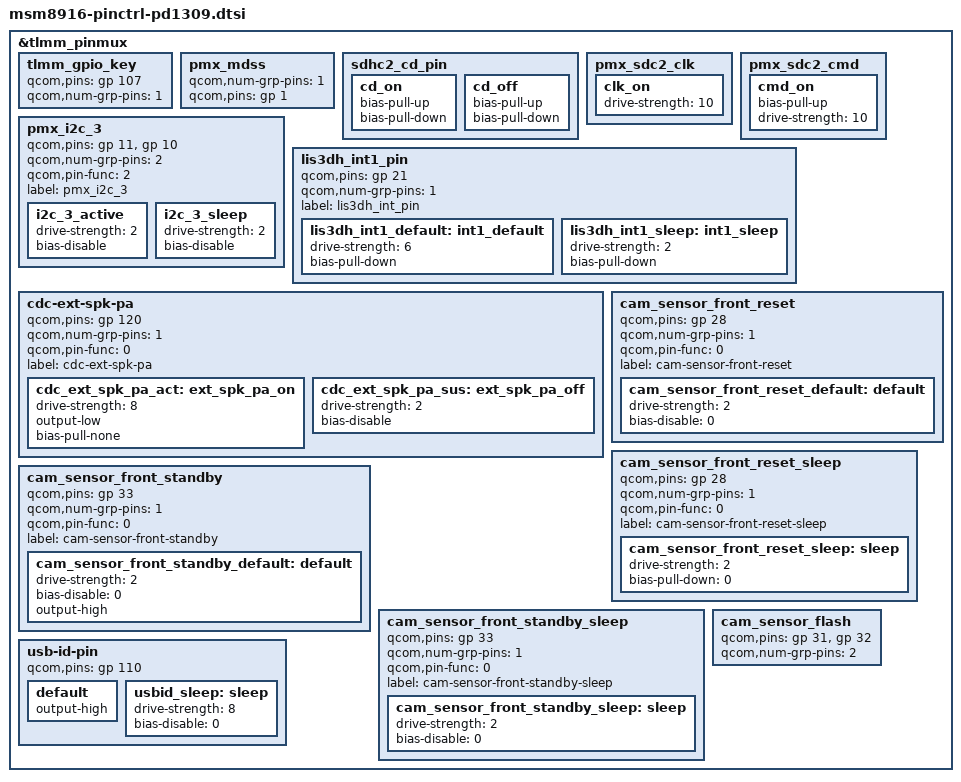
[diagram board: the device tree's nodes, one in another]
/* Copyright (c) 2020, The Linux Foundation. All rights reserved.
*  Copyright (c) 2020, the_shahnawaz_sheikh (sheikhshahnawaz41299).
*
* This program is free software; you can redistribute it and/or modify
* it under the terms of the GNU General Public License version 2 and
* only version 2 as published by the Free Software Foundation.
*
* This program is distributed in the hope that it will be useful,
* but WITHOUT ANY WARRANTY; without even the implied warranty of
* MERCHANTABILITY or FITNESS FOR A PARTICULAR PURPOSE.  See the
* GNU General Public License for more details.
*/
 
&tlmm_pinmux {

    tlmm_gpio_key {
		        /delete-property/ qcom,num-grp-pins;
				/delete-property/ qcom,pins;
				qcom,pins = <&gp 107>;
				qcom,num-grp-pins = <1>;
		};
    pmx_mdss {
				/delete-property/ qcom,num-grp-pins;
				/delete-property/ qcom,pins;
				qcom,num-grp-pins = <1>;
				qcom,pins = <&gp 1>;
		};
    
    /delete-node/ spi2_active;
		/delete-node/ spi2_suspend;
		/delete-node/ spi2_cs2_active;
		/delete-node/ spi2_cs2_suspend;
        
    sdhc2_cd_pin {

				cd_on {
					bias-pull-up;
					bias-pull-down;
				};

				cd_off {
                /delete-property/ bias-disable;
					bias-pull-up;
					bias-pull-down;
				};
		};
    
    pmx_sdc2_clk {
				clk_on {
					drive-strength = <10>;
				};
		};
	
	pmx_sdc2_cmd {
				cmd_on {
					bias-pull-up;
					drive-strength = <10>;
				};
			};
    
	pmx_i2c_3 {
		/* CLK, DATA */
		qcom,pins = <&gp 11>, <&gp 10>;
		qcom,num-grp-pins = <2>;
		qcom,pin-func = <2>;
		label = "pmx_i2c_3";

		i2c_3_active: i2c_3_active {
			drive-strength = <2>; /* 2 MA */
			bias-disable;		  /* No PULL */
		};

		i2c_3_sleep: i2c_3_sleep {
			drive-strength = <2>; /* 2 MA */
			bias-disable;		  /* No PULL */
		};
	};

	lis3dh_int1_pin {
		qcom,pins = <&gp 21>;
		qcom,num-grp-pins = <1>;
		label = "lis3dh_int_pin";
		lis3dh_int1_default: int1_default {
			drive-strength = <6>;
			bias-pull-down;
		};
		lis3dh_int1_sleep: int1_sleep {
			drive-strength = <2>;
			bias-pull-down;
		};
	};

	cdc-ext-spk-pa {
		qcom,pins = <&gp 120>;
		qcom,num-grp-pins = <1>;
		qcom,pin-func = <0>;
		label = "cdc-ext-spk-pa";
		cdc_ext_spk_pa_act: ext_spk_pa_on {
			drive-strength = <8>;
			output-low;
			bias-pull-none;
		};
		cdc_ext_spk_pa_sus: ext_spk_pa_off {
			drive-strength = <2>;
			bias-disable;
		};
	};

        
    cam_sensor_front_reset {
				qcom,pins = <&gp 28>;
				qcom,num-grp-pins = <1>;
				qcom,pin-func = <0>;
				label = "cam-sensor-front-reset";

				cam_sensor_front_reset_default:default {
					drive-strength = <2>;
					bias-disable = <0>;
					
				};
			};

			cam_sensor_front_reset_sleep {
				qcom,pins = <&gp 28>;
				qcom,num-grp-pins = <1>;
				qcom,pin-func = <0>;
				label = "cam-sensor-front-reset-sleep";

				cam_sensor_front_reset_sleep: sleep {
					drive-strength = <2>;
					bias-pull-down = <0>;
					
				};
			};

			cam_sensor_front_standby {
				qcom,pins = <&gp 33>;
				qcom,num-grp-pins = <1>;
				qcom,pin-func = <0>;
				label = "cam-sensor-front-standby";

			cam_sensor_front_standby_default: default {
					drive-strength = <2>;
					bias-disable = <0>;
					output-high;
					
				};
			};

			cam_sensor_front_standby_sleep {
				qcom,pins = <&gp 33>;
				qcom,num-grp-pins = <1>;
				qcom,pin-func = <0>;
				label = "cam-sensor-front-standby-sleep";

				cam_sensor_front_standby_sleep: sleep {
					drive-strength = <2>;
					bias-disable = <0>;
					
				};
			};
			
			cam_sensor_flash {
			    /delete-property/ qcom,num-grp-pins;
				/delete-property/ qcom,pins;
				qcom,pins = <&gp 31>, <&gp 32>;
				qcom,num-grp-pins = <2>;
			};

	usb-id-pin {
		qcom,pins = <&gp 110>;
		
		default {
					output-high;
				};

		usbid_sleep: sleep {
			drive-strength = <8>;
			bias-disable = <0>;
		};
	};
};
